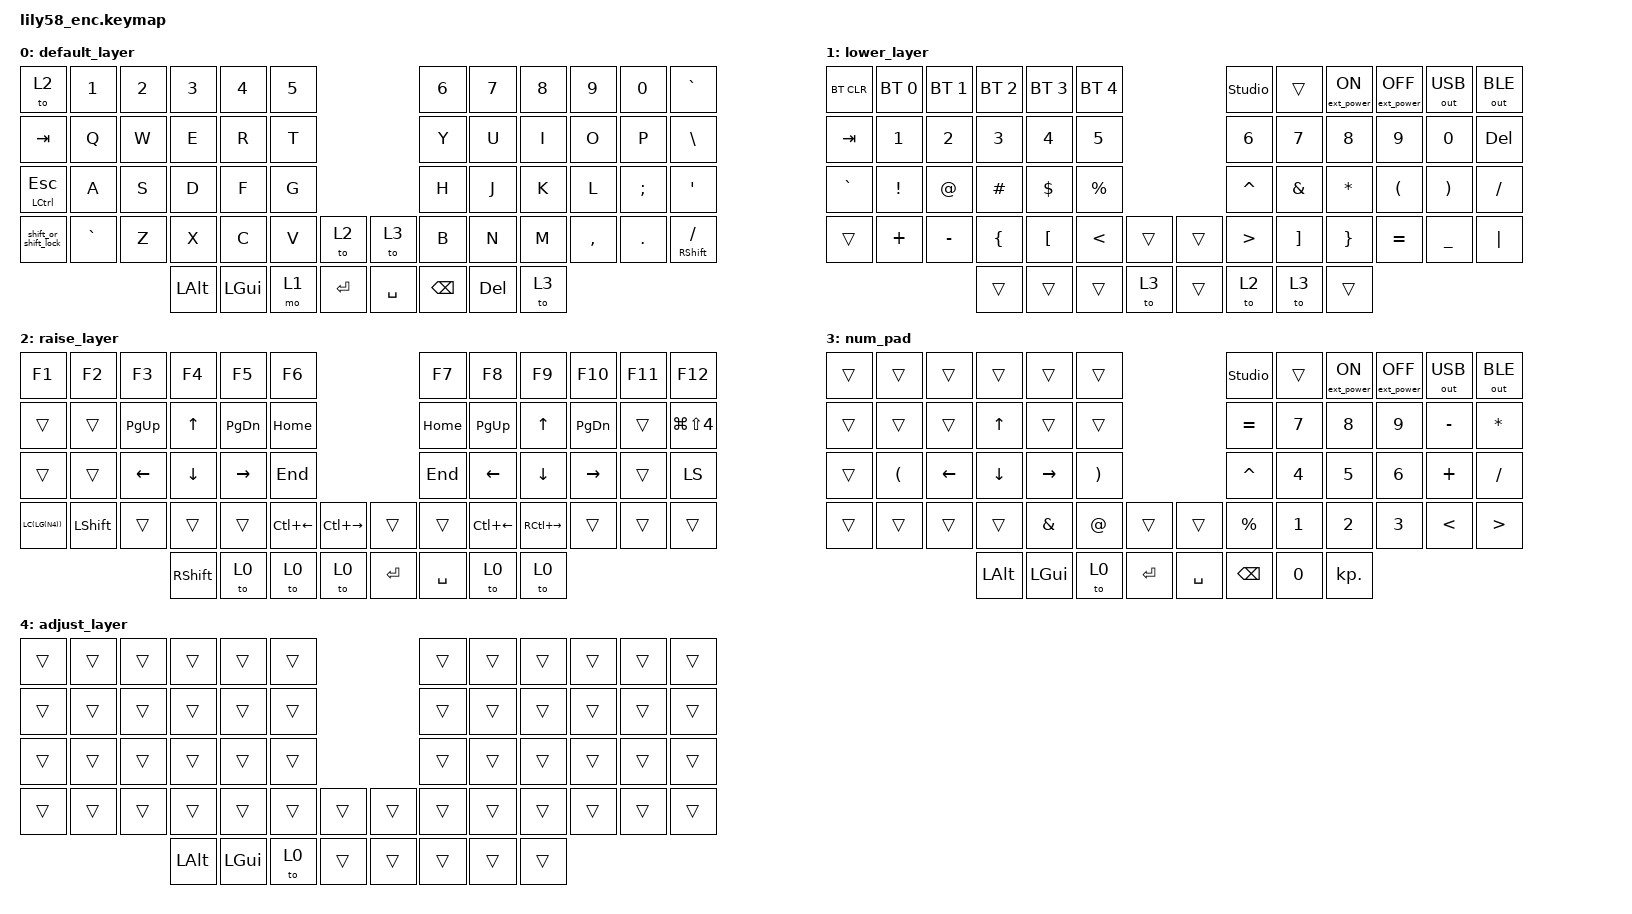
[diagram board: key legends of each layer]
/*
 * Copyright (c) 2020 The ZMK Contributors
 *
 * SPDX-License-Identifier: MIT
 */

#include <behaviors.dtsi>
#include <dt-bindings/zmk/bt.h>
#include <dt-bindings/zmk/ext_power.h>
#include <dt-bindings/zmk/keys.h>
#include <dt-bindings/zmk/outputs.h>

/ {
    behaviors {
        bspc_del: backspace_delete {
            compatible = "zmk,behavior-mod-morph";
            label = "BACKSPACE_DELETE";
            #binding-cells = <0>;
            bindings = <&kp BACKSPACE>, <&kp DELETE>;

            mods = <(MOD_LSFT|MOD_RSFT)>;
            keep-mods = <(MOD_RSFT)>;
        };

        shift_or_shift_lock: shift_or_shift_lock {
            compatible = "zmk,behavior-tap-dance";
            label = "SHIFT_OR_SHIFT_LOCK";
            #binding-cells = <0>;
            bindings = <&kp LEFT_SHIFT>, <&caps_word>;

            tapping-term-ms = <200>;
        };

        tap_kt_or_hold_to_mo_layer: tap_kt_or_hold_to_mo_layer {
            compatible = "zmk,behavior-hold-tap";
            label = "TAP_KT_OR_HOLD_TO_MO_LAYER";
            bindings = <&mo>, <&kt>;

            #binding-cells = <2>;
            flavor = "tap-preferred";
            tapping-term-ms = <200>;
            quick-tap-ms = <100>;
        };
    };

    combos {
        compatible = "zmk,combos";

        go_to_num_pad_layer {
            bindings = <&tog 3>;
            key-positions = <26 25 52>;
        };

        slash {
            bindings = <&kp KP_SLASH>;
            key-positions = <32 45>;
        };

        back_slash {
            bindings = <&kp BACKSLASH>;
            key-positions = <27 40>;
        };

        left_bracket {
            bindings = <&kp LEFT_BRACKET>;
            key-positions = <16 15>;
        };

        right_bracket {
            bindings = <&kp RIGHT_BRACKET>;
            key-positions = <19 20>;
        };

        left_parenthesis {
            bindings = <&kp LEFT_PARENTHESIS>;
            key-positions = <28 27>;
        };

        right_parenthesis {
            bindings = <&kp RIGHT_PARENTHESIS>;
            key-positions = <31 32>;
        };

        left_brace {
            bindings = <&kp LEFT_BRACE>;
            key-positions = <40 39>;
        };

        right_brace {
            bindings = <&kp RIGHT_BRACE>;
            key-positions = <45 46>;
        };

        pipe {
            bindings = <&kp PIPE>;
            key-positions = <19 16>;
        };

        minus {
            bindings = <&kp MINUS>;
            key-positions = <28 31>;
        };

        underscore {
            bindings = <&kp UNDERSCORE>;
            key-positions = <40 45>;
        };
    };

    keymap {
        compatible = "zmk,keymap";

        default_layer {
            // ------------------------------------------------------------------------------------------------------------
            // |  ESC  |  1  |  2  |  3   |  4   |  5   |                   |  6   |  7    |  8    |  9   |   0   |   `   |
            // |  TAB  |  Q  |  W  |  E   |  R   |  T   |                   |  Y   |  U    |  I    |  O   |   P   |   -   |
            // |  CTRL |  A  |  S  |  D   |  F   |  G   |                   |  H   |  J    |  K    |  L   |   ;   |   '   |
            // | SHIFT |  Z  |  X  |  C   |  V   |  B   |   "["  |  |  "]"  |  N   |  M    |  ,    |  .   |   /   |  ESC  |
            //                     | ALT  | GUI  | LOWER|  SPACE |  | ENTER | RAISE| BSPC  | GUI   |

            bindings = <
&to 2                 &kp N1     &kp N2  &kp N3    &kp N4    &kp N5                        &kp N6         &kp N7      &kp N8  &kp N9     &kp N0    &kp GRAVE
&kp TAB               &kp Q      &kp W   &kp E     &kp R     &kp T                         &kp Y          &kp U       &kp I   &kp O      &kp P     &kp BACKSLASH
&mt LCTRL ESCAPE      &kp A      &kp S   &kp D     &kp F     &kp G                         &kp H          &kp J       &kp K   &kp L      &kp SEMI  &kp SQT
&shift_or_shift_lock  &kp GRAVE  &kp Z   &kp X     &kp C     &kp V   &to 2      &to 3      &kp B          &kp N       &kp M   &kp COMMA  &kp DOT   &mt RIGHT_SHIFT SLASH
                                         &kp LALT  &kp LGUI  &mo 1   &kp ENTER  &kp SPACE  &kp BACKSPACE  &kp DELETE  &to 3
            >;

            sensor-bindings = <&inc_dec_kp C_VOLUME_UP C_VOLUME_DOWN>;
        };

        lower_layer {
            // ------------------------------------------------------------------------------------------------------------
            // | BTCLR | BT1 | BT2 |  BT3 |  BT4 |  BT5 |                   |      |       |       |      |       |       |
            // |  F1   |  F2 |  F3 |  F4  |  F5  |  F6  |                   |  F7  |  F8   |  F9   |  F10 |  F11  |  F12  |
            // |   `   |  !  |  @  |  #   |  $   |  %   |                   |  ^   |  &    |  *    |  (   |   )   |   ~   |
            // |       |     |     |      |      |      |        |  |       |      |  _    |  +    |  {   |   }   |  "|"  |
            //                     |      |      |      |        |  |       |      |       |       |

            bindings = <
&bt BT_CLR  &bt BT_SEL 0  &bt BT_SEL 1  &bt BT_SEL 2    &bt BT_SEL 3      &bt BT_SEL 4                   &studio_unlock    &trans             &ext_power EP_ON  &ext_power EP_OFF  &out OUT_USB    &out OUT_BLE
&kp TAB     &kp NUMBER_1  &kp NUMBER_2  &kp N3          &kp N4            &kp N5                         &kp N6            &kp N7             &kp N8            &kp N9             &kp N0          &kp DEL
&kp GRAVE   &kp EXCL      &kp AT        &kp HASH        &kp DOLLAR        &kp PRCNT                      &kp CARET         &kp AMPS           &kp ASTERISK      &kp LPAR           &kp RPAR        &kp SLASH
&trans      &kp PLUS      &kp MINUS     &kp LEFT_BRACE  &kp LEFT_BRACKET  &kp LESS_THAN  &trans  &trans  &kp GREATER_THAN  &kp RIGHT_BRACKET  &kp RBRC          &kp EQUAL          &kp UNDERSCORE  &kp PIPE
                                        &trans          &trans            &trans         &to 3   &trans  &to 2             &to 3              &trans
            >;

            sensor-bindings = <&inc_dec_kp C_VOLUME_UP C_VOLUME_DOWN>;
        };

        raise_layer {
            // ------------------------------------------------------------------------------------------------------------
            // |       |     |     |      |      |      |                   |      |       |       |      |       |       |
            // |   `   |  1  |  2  |  3   |  4   |  5   |                   |  6   |   7   |   8   |  9   |   0   |       |
            // |   F1  |  F2 |  F3 |  F4  |  F5  |  F6  |                   |      |   <-  |   v   |  ^   |  ->   |       |
            // |   F7  |  F8 |  F9 |  F10 |  F11 |  F12 |        |  |       |  +   |   -   |   =   |  [   |   ]   |   \   |
            //                     |      |      |      |        |  |       |      |       |       |

            bindings = <
&kp F1          &kp F2  &kp F3          &kp F4          &kp F5           &kp F6                                     &kp F7              &kp F8               &kp F9          &kp F10          &kp F11  &kp F12
&trans          &trans  &kp PAGE_UP     &kp UP_ARROW    &kp PAGE_DOWN    &kp HOME                                   &kp HOME            &kp PAGE_UP          &kp UP_ARROW    &kp PAGE_DOWN    &trans   &kp LG(LS(N4))
&trans          &trans  &kp LEFT_ARROW  &kp DOWN_ARROW  &kp RIGHT_ARROW  &kp END                                    &kp END             &kp LEFT_ARROW       &kp DOWN_ARROW  &kp RIGHT_ARROW  &trans   &kp LS(LC(LG(N4)))
&kp LEFT_SHIFT  &trans  &trans          &trans          &kp LC(LEFT)     &kp LC(RIGHT_ARROW)  &trans     &trans     &kp LC(LEFT_ARROW)  &kp RC(RIGHT_ARROW)  &trans          &trans           &trans   &kp RIGHT_SHIFT
                                        &to 0           &to 0            &to 0                &kp ENTER  &kp SPACE  &to 0               &to 0
            >;

            sensor-bindings = <&inc_dec_kp C_BRI_UP C_BRI_DN>;
        };

        num_pad {
            // ------------------------------------------------------------------------------------------------------------
            // |       |     |     |      |      |      |                   |      |       |       |      |       |       |
            // |   `   |  1  |  2  |  3   |  4   |  5   |                   |  6   |   7   |   8   |  9   |   0   |       |
            // |   F1  |  F2 |  F3 |  F4  |  F5  |  F6  |                   |      |   <-  |   v   |  ^   |  ->   |       |
            // |   F7  |  F8 |  F9 |  F10 |  F11 |  F12 |        |  |       |  +   |   -   |   =   |  [   |   ]   |   \   |
            //                     |      |      |      |        |  |       |      |       |       |

            bindings = <
&trans  &trans                &trans    &trans        &trans     &trans                                       &studio_unlock  &trans  &ext_power EP_ON  &ext_power EP_OFF  &out OUT_USB   &out OUT_BLE
&trans  &trans                &trans    &kp UP        &trans     &trans                                       &kp EQUAL       &kp N7  &kp N8            &kp N9             &kp MINUS      &kp ASTRK
&trans  &kp LEFT_PARENTHESIS  &kp LEFT  &kp DOWN      &kp RIGHT  &kp RIGHT_PARENTHESIS                        &kp CARET       &kp N4  &kp N5            &kp N6             &kp PLUS       &kp SLASH
&trans  &trans                &trans    &trans        &kp AMPS   &kp AT                 &trans     &trans     &kp PERCENT     &kp N1  &kp N2            &kp N3             &kp LESS_THAN  &kp GREATER_THAN
                                        &kp LEFT_ALT  &kp LGUI   &to 0                  &kp ENTER  &kp SPACE  &kp BACKSPACE   &kp N0  &kp KP_DOT
            >;

            sensor-bindings = <&inc_dec_kp C_VOLUME_UP C_VOLUME_DOWN>;
        };

        adjust_layer {
            // ------------------------------------------------------------------------------------------------------------
            // |       |     |     |      |      |      |                   |      |       |       |      |       |       |
            // |   `   |  1  |  2  |  3   |  4   |  5   |                   |  6   |   7   |   8   |  9   |   0   |       |
            // |   F1  |  F2 |  F3 |  F4  |  F5  |  F6  |                   |      |   <-  |   v   |  ^   |  ->   |       |
            // |   F7  |  F8 |  F9 |  F10 |  F11 |  F12 |        |  |       |  +   |   -   |   =   |  [   |   ]   |   \   |
            //                     |      |      |      |        |  |       |      |       |       |

            bindings = <
&trans  &trans  &trans  &trans        &trans    &trans                  &trans  &trans  &trans  &trans  &trans  &trans
&trans  &trans  &trans  &trans        &trans    &trans                  &trans  &trans  &trans  &trans  &trans  &trans
&trans  &trans  &trans  &trans        &trans    &trans                  &trans  &trans  &trans  &trans  &trans  &trans
&trans  &trans  &trans  &trans        &trans    &trans  &trans  &trans  &trans  &trans  &trans  &trans  &trans  &trans
                        &kp LEFT_ALT  &kp LGUI  &to 0   &trans  &trans  &trans  &trans  &trans
            >;

            sensor-bindings = <&inc_dec_kp C_VOLUME_UP C_VOLUME_DOWN>;
        };
    };
};
